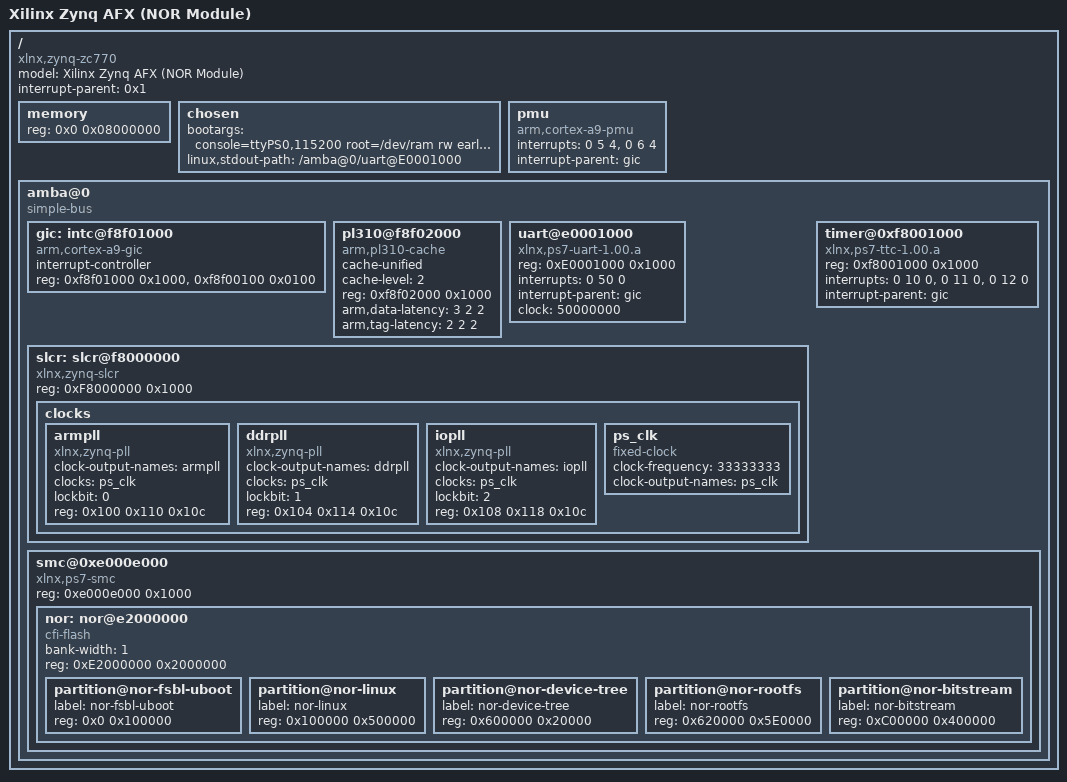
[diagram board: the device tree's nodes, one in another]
/dts-v1/;

/ {
	model = "Xilinx Zynq AFX (NOR Module)";
	compatible = "xlnx,zynq-zc770";
	#address-cells = <0x1>;
	#size-cells = <0x1>;
	interrupt-parent = <0x1>;

	memory {
		device_type = "memory";
		reg = <0x0 0x08000000>;
	};

	chosen {
		bootargs = "console=ttyPS0,115200 root=/dev/ram rw earlyprintk";
		linux,stdout-path = "/amba@0/uart@E0001000";
	};

	pmu {
		compatible = "arm,cortex-a9-pmu";
		interrupts = <0 5 4>, <0 6 4>;
		interrupt-parent = <&gic>;
	};

	amba@0 {
		compatible = "simple-bus";
		#address-cells = <0x1>;
		#size-cells = <0x1>;
		ranges;

		gic: intc@f8f01000 {
			interrupt-controller;
			compatible = "arm,cortex-a9-gic";
			#interrupt-cells = <3>;
			reg = < 0xf8f01000 0x1000 >,
			      < 0xf8f00100 0x0100 >;
		};

		pl310@f8f02000 {
                        compatible = "arm,pl310-cache";
                        cache-unified;
                        cache-level = <2>;
                        reg = <0xf8f02000 0x1000>;
                        arm,data-latency = <3 2 2>;
                        arm,tag-latency = <2 2 2>;
                };

		uart@e0001000 {
			compatible = "xlnx,ps7-uart-1.00.a";
			reg = <0xE0001000 0x1000>;
			interrupts = <0 50 0>;
			interrupt-parent = <&gic>;
			clock = <50000000>;
		};

		slcr: slcr@f8000000 {
			compatible = "xlnx,zynq-slcr";
			reg = <0xF8000000 0x1000>;
			clocks {
				#address-cells = <1>;
				#size-cells = <0>;
				armpll: armpll {
					#clock-cells = <0>;
					clock-output-names = "armpll";
					clocks = <&ps_clk>;
					compatible = "xlnx,zynq-pll";
					lockbit = <0>;
					reg = < 0x100 0x110 0x10c >;
				} ;
				ddrpll: ddrpll {
					#clock-cells = <0>;
					clock-output-names = "ddrpll";
					clocks = <&ps_clk>;
					compatible = "xlnx,zynq-pll";
					lockbit = <1>;
					reg = < 0x104 0x114 0x10c >;
				} ;
				iopll: iopll {
					#clock-cells = <0>;
					clock-output-names = "iopll";
					clocks = <&ps_clk>;
					compatible = "xlnx,zynq-pll";
					lockbit = <2>;
					reg = < 0x108 0x118 0x10c >;
				} ;
				ps_clk: ps_clk {
					#clock-cells = <0>;
					clock-frequency = <33333333>;
					clock-output-names = "ps_clk";
					compatible = "fixed-clock";
				} ;
			} ;
		};

		timer@0xf8001000 {
			compatible = "xlnx,ps7-ttc-1.00.a";
			reg = <0xf8001000 0x1000>;
			interrupts = <0 10 0>,<0 11 0>,<0 12 0>;
			interrupt-parent = <&gic>;
		};

		smc@0xe000e000 {
			compatible = "xlnx,ps7-smc";
			reg = <0xe000e000 0x1000>;
			#address-cells = <1>;
			#size-cells = <1>;
			ranges;

			nor: nor@e2000000 {
				compatible = "cfi-flash";
				bank-width = <1>;
				reg = <0xE2000000 0x2000000>; /* 32MB */
				#address-cells = <1>;
				#size-cells = <1>;

				partition@nor-fsbl-uboot {
					label = "nor-fsbl-uboot";
					reg = <0x0 0x100000>;
				};
				partition@nor-linux {
					label = "nor-linux";
					reg = <0x100000 0x500000>;
				};
				partition@nor-device-tree {
					label = "nor-device-tree";
					reg = <0x600000 0x20000>;
				};
				partition@nor-rootfs {
					label = "nor-rootfs";
					reg = <0x620000 0x5E0000>;
				};
				partition@nor-bitstream {
					label = "nor-bitstream";
					reg = <0xC00000 0x400000>;
				};
			};
		};
	};
};
